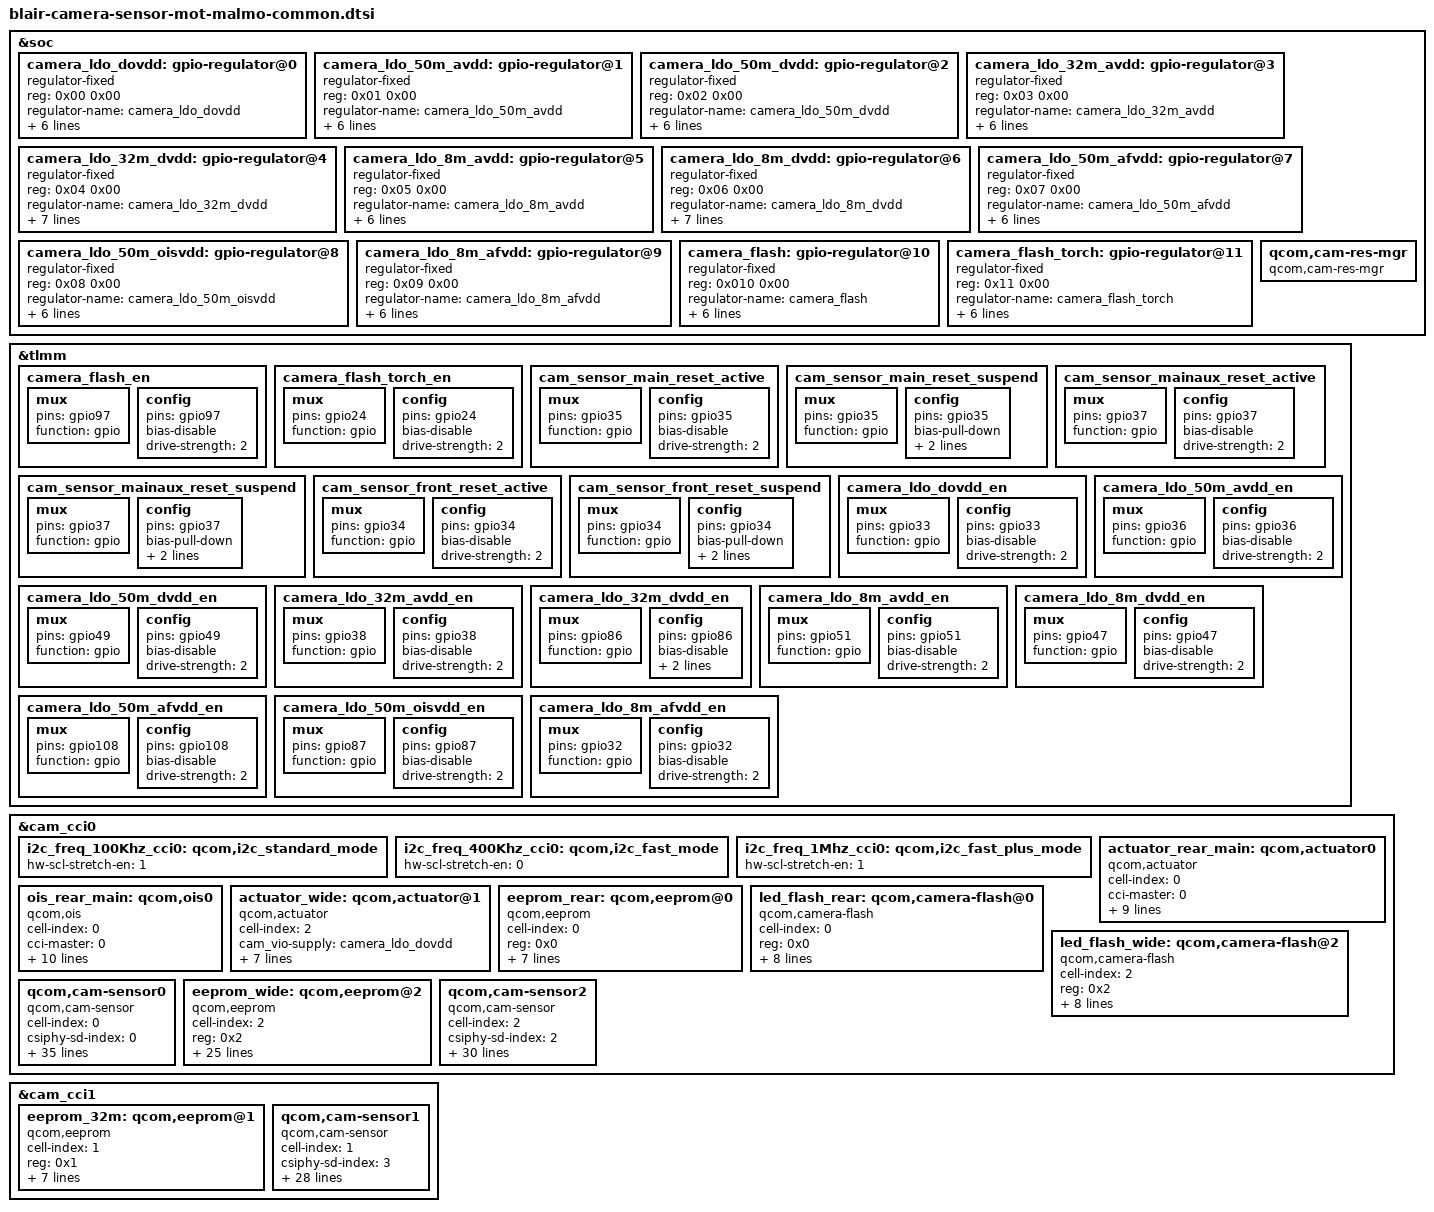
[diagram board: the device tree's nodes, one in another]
#include <dt-bindings/clock/qcom,gcc-blair.h>
#include <dt-bindings/msm-camera.h>
&soc {
	camera_ldo_dovdd: gpio-regulator@0 {
		compatible = "regulator-fixed";
		reg = <0x00 0x00>;
		regulator-name = "camera_ldo_dovdd";
		regulator-min-microvolt = <1800000>;
		regulator-max-microvolt = <1800000>;
		regulator-enable-ramp-delay = <233>;
		enable-active-high;
		gpio = <&tlmm 33 0>;
		pinctrl-names = "default";
		pinctrl-0 = <&camera_ldo_dovdd_en>;
	};

	camera_ldo_50m_avdd: gpio-regulator@1 {
		compatible = "regulator-fixed";
		reg = <0x01 0x00>;
		regulator-name = "camera_ldo_50m_avdd";
		regulator-min-microvolt = <2800000>;
		regulator-max-microvolt = <2800000>;
		regulator-enable-ramp-delay = <233>;
		enable-active-high;
		gpio = <&tlmm 36 0>;
		pinctrl-names = "default";
		pinctrl-0 = <&camera_ldo_50m_avdd_en>;
	};

	camera_ldo_50m_dvdd: gpio-regulator@2 {
		compatible = "regulator-fixed";
		reg = <0x02 0x00>;
		regulator-name = "camera_ldo_50m_dvdd";
		regulator-min-microvolt = <1100000>;
		regulator-max-microvolt = <1100000>;
		regulator-enable-ramp-delay = <233>;
		enable-active-high;
		gpio = <&tlmm 49 0>;
		pinctrl-names = "default";
		pinctrl-0 = <&camera_ldo_50m_dvdd_en>;
	};

	camera_ldo_32m_avdd: gpio-regulator@3 {
		compatible = "regulator-fixed";
		reg = <0x03 0x00>;
		regulator-name = "camera_ldo_32m_avdd";
		regulator-min-microvolt = <2800000>;
		regulator-max-microvolt = <2800000>;
		regulator-enable-ramp-delay = <233>;
		enable-active-high;
		gpio = <&tlmm 38 0>;
		pinctrl-names = "default";
		pinctrl-0 = <&camera_ldo_32m_avdd_en>;
	};

	camera_ldo_32m_dvdd: gpio-regulator@4 {
		compatible = "regulator-fixed";
		reg = <0x04 0x00>;
		regulator-name = "camera_ldo_32m_dvdd";
		regulator-min-microvolt = <1050000>;
		regulator-max-microvolt = <1050000>;
		regulator-enable-ramp-delay = <233>;
		enable-active-high;
		gpio = <&tlmm 86 0>;
		pinctrl-names = "default";
		pinctrl-0 = <&camera_ldo_32m_dvdd_en>;
		vin-supply = <&S6A>;
	};

	camera_ldo_8m_avdd: gpio-regulator@5 {
		compatible = "regulator-fixed";
		reg = <0x05 0x00>;
		regulator-name = "camera_ldo_8m_avdd";
		regulator-min-microvolt = <2800000>;
		regulator-max-microvolt = <2800000>;
		regulator-enable-ramp-delay = <233>;
		enable-active-high;
		gpio = <&tlmm 51 0>;
		pinctrl-names = "default";
		pinctrl-0 = <&camera_ldo_8m_avdd_en>;
	};

	camera_ldo_8m_dvdd: gpio-regulator@6 {
		compatible = "regulator-fixed";
		reg = <0x06 0x00>;
		regulator-name = "camera_ldo_8m_dvdd";
		regulator-min-microvolt = <1200000>;
		regulator-max-microvolt = <1200000>;
		regulator-enable-ramp-delay = <233>;
		enable-active-high;
		gpio = <&tlmm 47 0>;
		pinctrl-names = "default";
		pinctrl-0 = <&camera_ldo_8m_dvdd_en>;
		vin-supply = <&S6A>;
	};

	camera_ldo_50m_afvdd: gpio-regulator@7 {
		compatible = "regulator-fixed";
		reg = <0x07 0x00>;
		regulator-name = "camera_ldo_50m_afvdd";
		regulator-min-microvolt = <2800000>;
		regulator-max-microvolt = <2800000>;
		regulator-enable-ramp-delay = <233>;
		enable-active-high;
		gpio = <&tlmm 108 0>;
		pinctrl-names = "default";
		pinctrl-0 = <&camera_ldo_50m_afvdd_en>;
	};

	camera_ldo_50m_oisvdd: gpio-regulator@8 {
		compatible = "regulator-fixed";
		reg = <0x08 0x00>;
		regulator-name = "camera_ldo_50m_oisvdd";
		regulator-min-microvolt = <2800000>;
		regulator-max-microvolt = <2800000>;
		regulator-enable-ramp-delay = <233>;
		enable-active-high;
		gpio = <&tlmm 87 0>;
		pinctrl-names = "default";
		pinctrl-0 = <&camera_ldo_50m_oisvdd_en>;
	};

	camera_ldo_8m_afvdd: gpio-regulator@9 {
		compatible = "regulator-fixed";
		reg = <0x09 0x00>;
		regulator-name = "camera_ldo_8m_afvdd";
		regulator-min-microvolt = <2800000>;
		regulator-max-microvolt = <2800000>;
		regulator-enable-ramp-delay = <233>;
		enable-active-high;
		gpio = <&tlmm 32 0>;
		pinctrl-names = "default";
		pinctrl-0 = <&camera_ldo_8m_afvdd_en>;
	};

	camera_flash: gpio-regulator@10 {
		compatible = "regulator-fixed";
		reg = <0x010 0x00>;
		regulator-name = "camera_flash";
		regulator-min-microvolt = <1800000>;
		regulator-max-microvolt = <1800000>;
		regulator-enable-ramp-delay = <233>;
		enable-active-high;
		gpio = <&tlmm 97 0>;
		pinctrl-names = "default";
		pinctrl-0 = <&camera_flash_en>;
	};

	camera_flash_torch: gpio-regulator@11 {
		compatible = "regulator-fixed";
		reg = <0x11 0x00>;
		regulator-name = "camera_flash_torch";
		regulator-min-microvolt = <1800000>;
		regulator-max-microvolt = <1800000>;
		regulator-enable-ramp-delay = <233>;
		enable-active-high;
		gpio = <&tlmm 24 0>;
		pinctrl-names = "default";
		pinctrl-0 = <&camera_flash_torch_en>;
	};

	qcom,cam-res-mgr {
		compatible = "qcom,cam-res-mgr";
		status = "ok";
	};
};

&tlmm {
	camera_flash_en: camera_flash_en {
		mux {
			pins = "gpio97";
			function = "gpio";
		};

		config {
			pins = "gpio97";
			bias-disable; /* No PULL */
			drive-strength = <2>; /* 2 MA */
		};
	};

	camera_flash_torch_en: camera_flash_torch_en {
		mux {
			pins = "gpio24";
			function = "gpio";
		};

		config {
			pins = "gpio24";
			bias-disable; /* No PULL */
			drive-strength = <2>; /* 2 MA */
		};
	};

	cam_sensor_main_reset_active: cam_sensor_main_reset_active {
		mux {
			pins = "gpio35";
			function = "gpio";
		};

		config {
			pins = "gpio35";
			bias-disable; /* No PULL */
			drive-strength = <2>; /* 2 MA */
		};
	};

	cam_sensor_main_reset_suspend: cam_sensor_main_reset_suspend {
		mux {
			pins = "gpio35";
			function = "gpio";
		};

		config {
			pins = "gpio35";
			bias-pull-down; /* PULL DOWN */
			drive-strength = <2>; /* 2 MA */
			output-low;
		};
	};

	cam_sensor_mainaux_reset_active: cam_sensor_mainaux_reset_active {
		mux {
			pins = "gpio37";
			function = "gpio";
		};

		config {
			pins = "gpio37";
			bias-disable; /* No PULL */
			drive-strength = <2>; /* 2 MA */
		};
	};

	cam_sensor_mainaux_reset_suspend: cam_sensor_mainaux_reset_suspend {
		mux {
			pins = "gpio37";
			function = "gpio";
		};

		config {
			pins = "gpio37";
			bias-pull-down; /* PULL DOWN */
			drive-strength = <2>; /* 2 MA */
			output-low;
		};
	};
	cam_sensor_front_reset_active: cam_sensor_front_reset_active {
		mux {
			pins = "gpio34";
			function = "gpio";
		};

		config {
			pins = "gpio34";
			bias-disable; /* No PULL */
			drive-strength = <2>; /* 2 MA */
		};
	};

	cam_sensor_front_reset_suspend: cam_sensor_front_reset_suspend {
		mux {
			pins = "gpio34";
			function = "gpio";
		};

		config {
			pins = "gpio34";
			bias-pull-down; /* PULL DOWN */
			drive-strength = <2>; /* 2 MA */
			output-low;
		};
	};
	camera_ldo_dovdd_en: camera_ldo_dovdd_en {
		mux {
			pins = "gpio33";
			function = "gpio";
		};

		config {
			pins = "gpio33";
			bias-disable; /* No PULL */
			drive-strength = <2>; /* 2 MA */
		};
	};
	camera_ldo_50m_avdd_en: camera_ldo_50m_avdd_en {
		mux {
			pins = "gpio36";
			function = "gpio";
		};

		config {
			pins = "gpio36";
			bias-disable; /* No PULL */
			drive-strength = <2>; /* 2 MA */
		};
	};
	camera_ldo_50m_dvdd_en: camera_ldo_50m_dvdd_en {
		mux {
			pins = "gpio49";
			function = "gpio";
		};

		config {
			pins = "gpio49";
			bias-disable; /* No PULL */
			drive-strength = <2>; /* 2 MA */
		};
	};
	camera_ldo_32m_avdd_en: camera_ldo_32m_avdd_en {
		mux {
			pins = "gpio38";
			function = "gpio";
		};

		config {
			pins = "gpio38";
			bias-disable; /* No PULL */
			drive-strength = <2>; /* 2 MA */
		};
	};

	camera_ldo_32m_dvdd_en: camera_ldo_32m_dvdd_en {
		mux {
			pins = "gpio86";
			function = "gpio";
		};

		config {
			pins = "gpio86";
			bias-disable; /* No PULL */
			drive-strength = <2>; /* 2 MA */
			qcom,apps;
		};
	};
	camera_ldo_8m_avdd_en: camera_ldo_8m_avdd_en {
		mux {
			pins = "gpio51";
			function = "gpio";
		};

		config {
			pins = "gpio51";
			bias-disable; /* No PULL */
			drive-strength = <2>; /* 2 MA */
		};
	};

	camera_ldo_8m_dvdd_en: camera_ldo_8m_dvdd_en {
		mux {
			pins = "gpio47";
			function = "gpio";
		};

		config {
			pins = "gpio47";
			bias-disable; /* No PULL */
			drive-strength = <2>; /* 2 MA */
		};
	};

	camera_ldo_50m_afvdd_en: camera_ldo_50m_afvdd_en {
		mux {
			pins = "gpio108";
			function = "gpio";
		};

		config {
			pins = "gpio108";
			bias-disable; /* No PULL */
			drive-strength = <2>; /* 2 MA */
		};
	};

	camera_ldo_50m_oisvdd_en: camera_ldo_50m_oisvdd_en {
		mux {
			pins = "gpio87";
			function = "gpio";
		};

		config {
			pins = "gpio87";
			bias-disable; /* No PULL */
			drive-strength = <2>; /* 2 MA */
		};
	};

	camera_ldo_8m_afvdd_en: camera_ldo_8m_afvdd_en {
		mux {
			pins = "gpio32";
			function = "gpio";
		};

		config {
			pins = "gpio32";
			bias-disable; /* No PULL */
			drive-strength = <2>; /* 2 MA */
		};
	};
};

&cam_cci0 {
	i2c_freq_100Khz_cci0: qcom,i2c_standard_mode {
		hw-scl-stretch-en = <1>;
	};

	i2c_freq_400Khz_cci0: qcom,i2c_fast_mode {
		hw-scl-stretch-en = <0>;
	};

	i2c_freq_1Mhz_cci0: qcom,i2c_fast_plus_mode {
		hw-scl-stretch-en = <1>;
	};

	actuator_rear_main:qcom,actuator0{
		cell-index = <0>;
		compatible = "qcom,actuator";
		cci-master = <0>;
		cam_vio-supply = <&camera_ldo_dovdd>;
		cam_vaf-supply = <&camera_ldo_50m_afvdd>;
		cam_v_custom1-supply = <&camera_ldo_50m_oisvdd>;
		regulator-names = "cam_vio", "cam_vaf", "cam_v_custom1";
		rgltr-cntrl-support;
		rgltr-min-voltage = <1800000 2800000 2800000>;
		rgltr-max-voltage = <1800000 2800000 2800000>;
		rgltr-load-current = <500 300000 30000>;
		status = "ok";
	};

	ois_rear_main:qcom,ois0{
		cell-index = <0>;
		compatible = "qcom,ois";
		cci-master = <0>;
		cam_vio-supply = <&camera_ldo_dovdd>;
		cam_vaf-supply = <&camera_ldo_50m_afvdd>;
		cam_v_custom1-supply = <&camera_ldo_50m_oisvdd>;
		regulator-names = "cam_vio", "cam_vaf", "cam_v_custom1";
		rgltr-cntrl-support;
		rgltr-min-voltage = <1800000 2800000 2800000>;
		rgltr-max-voltage = <1800000 2800000 2800000>;
		rgltr-load-current = <500 300000 30000>;
		status = "ok";
		ois-name = "aw86006";
	};

	actuator_wide: qcom,actuator@1 {
		cell-index = <2>;
		compatible = "qcom,actuator";
		cam_vio-supply = <&camera_ldo_dovdd>;
		cam_vaf-supply = <&camera_ldo_8m_afvdd>;
		regulator-names = "cam_vio", "cam_vaf";
		rgltr-cntrl-support;
		rgltr-min-voltage = <1800000 2800000>;
		rgltr-max-voltage = <1800000 2800000>;
		rgltr-load-current = <120000 100000>;
		cci-master = <1>;
		status = "ok";
	};

	eeprom_rear: qcom,eeprom@0 {
		cell-index = <0>;
		reg = <0x0>;
		compatible = "qcom,eeprom";
		cam_vio-supply = <&camera_ldo_dovdd>;
		regulator-names = "cam_vio";
		rgltr-cntrl-support;
		rgltr-min-voltage = <1800000>;
		rgltr-max-voltage = <1800000>;
		rgltr-load-current = <120000>;
		cci-master = <0>;
		status = "ok";
	};

	led_flash_rear: qcom,camera-flash@0 {
		cell-index = <0>;
		reg = <0x0>;
		compatible = "qcom,camera-flash";
		flash-type = <CAM_FLASH_TYPE_I2C>;
		cam_vio-supply = <&camera_ldo_dovdd>;
		regulator-names = "cam_vio";
		rgltr-cntrl-support;
		rgltr-min-voltage = <1800000>;
		rgltr-max-voltage = <1800000>;
		rgltr-load-current = <100000>;
		cci-master = <1>;
		status = "ok";
	};

	led_flash_wide: qcom,camera-flash@2 {
		cell-index = <2>;
		reg = <0x2>;
		compatible = "qcom,camera-flash";
		flash-type = <CAM_FLASH_TYPE_I2C>;
		cam_vio-supply = <&camera_ldo_dovdd>;
		regulator-names = "cam_vio";
		rgltr-cntrl-support;
		rgltr-min-voltage = <1800000>;
		rgltr-max-voltage = <1800000>;
		rgltr-load-current = <100000>;
		cci-master = <1>;
		status = "ok";
	};

	qcom,cam-sensor0 {
		cell-index = <0>;
		compatible = "qcom,cam-sensor";
		csiphy-sd-index = <0>;
		sensor-position-roll = <90>;
		sensor-position-pitch = <0>;
		sensor-position-yaw = <180>;
		actuator-src = <&actuator_rear_main>;
		ois-src = <&ois_rear_main>;
		eeprom-src = <&eeprom_rear>;
		led-flash-src = <&led_flash_rear>;
		cam_vio-supply = <&camera_ldo_dovdd>;
		cam_vana-supply = <&camera_ldo_50m_avdd>;
		cam_vdig-supply = <&camera_ldo_50m_dvdd>;
		cam_clk-supply = <&gcc_camss_top_gdsc>;
		regulator-names =  "cam_vaf", "cam_vio", "cam_vana", "cam_v_custom1", "cam_vdig",
		    "cam_clk";
		rgltr-cntrl-support;
		rgltr-min-voltage = <2800000 1800000 2800000 3300000 1100000 0>;
		rgltr-max-voltage = <2800000 1800000 2800000 3300000 1100000 0>;
		rgltr-load-current = <105000 80000 80000 105000 105000 0>;
		gpio-no-mux = <0>;
		pinctrl-names = "cam_default", "cam_suspend";
		pinctrl-0 = <&cam_sensor_mclk0_active
				&cam_sensor_main_reset_active>;
		pinctrl-1 = <&cam_sensor_mclk0_suspend
				&cam_sensor_main_reset_suspend>;
		gpios = <&tlmm 29 0>,
			<&tlmm 35 0>;
		gpio-reset = <1>;
		gpio-req-tbl-num = <0 1>;
		gpio-req-tbl-flags = <1 0>;
		gpio-req-tbl-label = "CAMIF_MCLK0",
					"CAM_RESET0";
		sensor-mode = <0>;
		cci-master = <0>;
		status = "ok";
		clocks = <&gcc GCC_CAMSS_MCLK0_CLK>;
		clock-names = "cam_clk";
		clock-cntl-level = "turbo";
		clock-rates = <24000000>;
	};

	eeprom_wide: qcom,eeprom@2 {
		cell-index = <2>;
		reg = <0x2>;
		compatible = "qcom,eeprom";
		cam_vio-supply = <&camera_ldo_dovdd>;
		cam_vana-supply = <&camera_ldo_8m_avdd>;
		cam_vdig-supply = <&camera_ldo_8m_dvdd>;
		cam_clk-supply = <&gcc_camss_top_gdsc>;
		regulator-names = "cam_vio", "cam_vana", "cam_vdig",
		    "cam_clk";
		rgltr-cntrl-support;
		rgltr-min-voltage = <1800000 2800000 1200000 0>;
		rgltr-max-voltage = <1800000 2800000 1200000 0>;
		rgltr-load-current = <120000 80000 1200000 0>;
		gpio-no-mux = <0>;
		pinctrl-names = "cam_default", "cam_suspend";
		pinctrl-0 = <&cam_sensor_mclk2_active
				&cam_sensor_mainaux_reset_active>;
		pinctrl-1 = <&cam_sensor_mclk2_suspend
				&cam_sensor_mainaux_reset_suspend>;
		gpios = <&tlmm 31 0>,
			<&tlmm 37 0>;
		gpio-reset = <1>;
		gpio-req-tbl-num = <0 1>;
		gpio-req-tbl-flags = <1 0>;
		gpio-req-tbl-label = "CAMIF_MCLK2",
					"CAM_RESET3";
		sensor-mode = <0>;
		cci-master = <1>;
		status = "ok";
		clocks = <&gcc GCC_CAMSS_MCLK2_CLK>;
		clock-names = "cam_clk";
		clock-cntl-level = "turbo";
		clock-rates = <24000000>;
	};

	qcom,cam-sensor2 {
		cell-index = <2>;
		compatible = "qcom,cam-sensor";
		csiphy-sd-index = <2>;
		sensor-position-roll = <90>;
		sensor-position-pitch = <0>;
		sensor-position-yaw = <180>;
		actuator-src = <&actuator_wide>;
		//eeprom-src = <&eeprom_wide>;
		led-flash-src = <&led_flash_wide>;
		cam_vio-supply = <&camera_ldo_dovdd>;
		cam_vana-supply = <&camera_ldo_8m_avdd>;
		cam_vdig-supply = <&camera_ldo_8m_dvdd>;
		cam_clk-supply = <&gcc_camss_top_gdsc>;
		regulator-names = "cam_vio", "cam_vana", "cam_vdig",
		    "cam_clk";
		rgltr-cntrl-support;
		rgltr-min-voltage = <1800000 2800000 1200000 0>;
		rgltr-max-voltage = <1800000 2800000 1200000 0>;
		rgltr-load-current = <120000 80000 1200000 0>;
		gpio-no-mux = <0>;
		pinctrl-names = "cam_default", "cam_suspend";
		pinctrl-0 = <&cam_sensor_mclk2_active
				&cam_sensor_mainaux_reset_active>;
		pinctrl-1 = <&cam_sensor_mclk2_suspend
				&cam_sensor_mainaux_reset_suspend>;
		gpios = <&tlmm 31 0>,
			<&tlmm 37 0>;
		gpio-reset = <1>;
		gpio-req-tbl-num = <0 1>;
		gpio-req-tbl-flags = <1 0>;
		gpio-req-tbl-label = "CAMIF_MCLK2",
					"CAM_RESET3";
		sensor-mode = <0>;
		cci-master = <1>;
		status = "ok";
		clocks = <&gcc GCC_CAMSS_MCLK2_CLK>;
		clock-names = "cam_clk";
		clock-cntl-level = "turbo";
		clock-rates = <24000000>;
	};

};

&cam_cci1 {
	eeprom_32m: qcom,eeprom@1 {
		cell-index = <1>;
		reg = <0x1>;
		compatible = "qcom,eeprom";
		cam_vio-supply = <&camera_ldo_dovdd>;
		regulator-names = "cam_vio";
		rgltr-cntrl-support;
		rgltr-min-voltage = <1800000>;
		rgltr-max-voltage = <1800000>;
		rgltr-load-current = <120000>;
		cci-master = <0>;
		status = "ok";
	};

	qcom,cam-sensor1 {
		cell-index = <1>;
		compatible = "qcom,cam-sensor";
		csiphy-sd-index = <3>;
		sensor-position-roll = <270>;
		sensor-position-pitch = <0>;
		sensor-position-yaw = <0>;
		//eeprom-src = <&eeprom_32m>;
		cam_vio-supply = <&camera_ldo_dovdd>;
		cam_vana-supply = <&camera_ldo_32m_avdd>;
		cam_vdig-supply = <&camera_ldo_32m_dvdd>;
		cam_clk-supply = <&gcc_camss_top_gdsc>;
		regulator-names = "cam_vio", "cam_vana", "cam_vdig",
		    "cam_clk";
		rgltr-cntrl-support;
		rgltr-min-voltage = <1800000 2800000 1050000 0>;
		rgltr-max-voltage = <1800000 2800000 1050000 0>;
		rgltr-load-current = <120000 80000 1200000 0>;
		gpio-no-mux = <0>;
		pinctrl-names = "cam_default", "cam_suspend";
		pinctrl-0 = <&cam_sensor_mclk1_active
				&cam_sensor_front_reset_active>;
		pinctrl-1 = <&cam_sensor_mclk1_suspend
				&cam_sensor_front_reset_suspend>;
		gpios = <&tlmm 30 0>,
			<&tlmm 34 0>;
		gpio-reset = <1>;
		gpio-req-tbl-num = <0 1 >;
		gpio-req-tbl-flags = <1 0 >;
		gpio-req-tbl-label = "CAMIF_MCLK1",
					"CAM_RESET0";
		sensor-mode = <1>;
		cci-master = <0>;
		status = "ok";
		clocks = <&gcc GCC_CAMSS_MCLK1_CLK>;
		clock-names = "cam_clk";
		clock-cntl-level = "turbo";
		clock-rates = <24000000>;
	};
};
